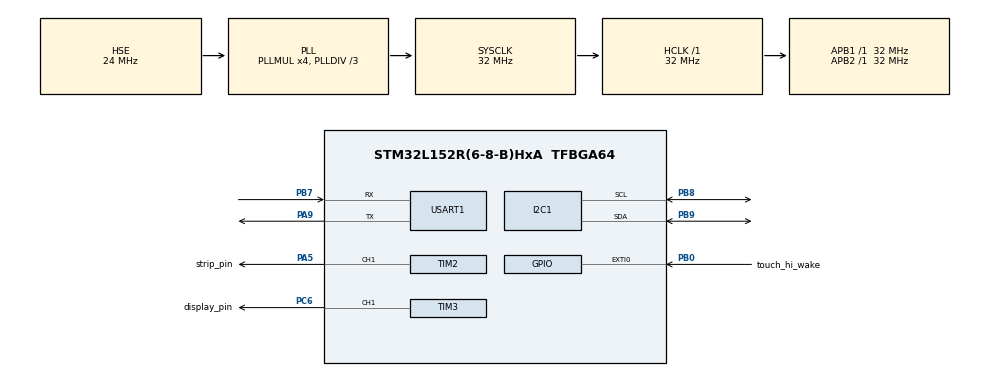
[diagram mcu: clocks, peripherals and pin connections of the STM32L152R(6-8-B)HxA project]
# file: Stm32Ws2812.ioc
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Dma.Request0=TIM2_CH1
Dma.Request1=TIM3_CH1/TRIG
Dma.TIM2_CH1.0.Direction=DMA_MEMORY_TO_PERIPH
Dma.TIM2_CH1.0.Instance=DMA1_Channel5
Dma.TIM2_CH1.0.MemDataAlignment=DMA_MDATAALIGN_HALFWORD
Dma.TIM2_CH1.0.MemInc=DMA_MINC_ENABLE
Dma.TIM2_CH1.0.Mode=DMA_CIRCULAR
Dma.TIM2_CH1.0.PeriphDataAlignment=DMA_PDATAALIGN_HALFWORD
Dma.TIM2_CH1.0.PeriphInc=DMA_PINC_DISABLE
Dma.TIM2_CH1.0.Priority=DMA_PRIORITY_LOW
Dma.TIM3_CH1/TRIG.1.Direction=DMA_PERIPH_TO_MEMORY
Dma.TIM3_CH1/TRIG.1.Instance=DMA1_Channel6
Dma.TIM3_CH1/TRIG.1.MemDataAlignment=DMA_MDATAALIGN_HALFWORD
Dma.TIM3_CH1/TRIG.1.MemInc=DMA_MINC_ENABLE
Dma.TIM3_CH1/TRIG.1.Mode=DMA_CIRCULAR
Dma.TIM3_CH1/TRIG.1.PeriphDataAlignment=DMA_PDATAALIGN_HALFWORD
Dma.TIM3_CH1/TRIG.1.PeriphInc=DMA_PINC_DISABLE
Dma.TIM3_CH1/TRIG.1.Priority=DMA_PRIORITY_LOW
FREERTOS.Mutexes01=cfgMutex,Dynamic,NULL
FREERTOS.Tasks01=ledsTask,0,128,LedsTask,Default,NULL,Dynamic,NULL,NULL;buttonsTask,0,128,ButtonsTask,Default,NULL,Dynamic,NULL,NULL;bleTask,0,256,BleTask,Default,NULL,Dynamic,NULL,NULL
FREERTOS.configTOTAL_HEAP_SIZE=4096
Mcu.Family=STM32L1
Mcu.Name=STM32L152R(6-8-B)HxA
Mcu.Package=TFBGA64
NVIC.DMA1_Channel5_IRQn=true\:5\:0\:false\:false\:true\:true\:false
NVIC.DMA1_Channel6_IRQn=true\:5\:0\:false\:false\:true\:true\:false
NVIC.EXTI0_IRQn=true\:5\:0\:false\:false\:true\:true\:true
NVIC.PriorityGroup=NVIC_PRIORITYGROUP_4
NVIC.TIM4_IRQn=true\:0\:0\:false\:false\:true\:false\:false
NVIC.TimeBase=TIM4_IRQn
NVIC.TimeBaseIP=TIM4
PA13.Mode=JTAG_5_pins
PA13.Signal=SYS_JTMS-SWDIO
PA14.Mode=JTAG_5_pins
PA14.Signal=SYS_JTCK-SWCLK
PA15.Mode=JTAG_5_pins
PA15.Signal=SYS_JTDI
PA5.GPIO_Label=strip_pin
PA5.GPIO_Speed=GPIO_SPEED_FREQ_VERY_HIGH
PA5.Signal=S_TIM2_CH1_ETR
PA9.Mode=Asynchronous
PA9.Signal=USART1_TX
PB0.GPIO_Label=touch_hi_wake
PB0.GPIO_PuPd=GPIO_PULLUP
PB0.Signal=GPXTI0
PB3.Mode=JTAG_5_pins
PB3.Signal=SYS_JTDO-TRACESWO
PB4.Mode=JTAG_5_pins
PB4.Signal=SYS_JTRST
PB7.Mode=Asynchronous
PB7.Signal=USART1_RX
PB8.Mode=I2C
PB8.Signal=I2C1_SCL
PB9.Mode=I2C
PB9.Signal=I2C1_SDA
PC14-OSC32_IN.Mode=LSE-External-Oscillator
PC14-OSC32_IN.Signal=RCC_OSC32_IN
PC15-OSC32_OUT.Mode=LSE-External-Oscillator
PC15-OSC32_OUT.Signal=RCC_OSC32_OUT
PC6.GPIO_Label=display_pin
PC6.GPIO_Speed=GPIO_SPEED_FREQ_VERY_HIGH
PC6.Signal=S_TIM3_CH1
PH0-OSC_IN.Mode=HSE-External-Oscillator
PH0-OSC_IN.Signal=RCC_OSC_IN
PH1-OSC_OUT.Mode=HSE-External-Oscillator
PH1-OSC_OUT.Signal=RCC_OSC_OUT
ProjectManager.HeapSize=0x200
ProjectManager.StackSize=0x400
ProjectManager.TargetToolchain=TrueSTUDIO
RCC.48MHZClocksFreq_Value=48000000
RCC.AHBFreq_Value=32000000
RCC.APB1Freq_Value=32000000
RCC.APB1TimFreq_Value=32000000
RCC.APB2Freq_Value=32000000
RCC.APB2TimFreq_Value=32000000
RCC.HCLKFreq_Value=32000000
RCC.HSE_VALUE=24000000
RCC.HSI_VALUE=16000000
RCC.MSI_VALUE=2097000
RCC.PLLDIV=RCC_PLL_DIV3
RCC.PLLMUL=RCC_PLL_MUL4
RCC.PLLSourceVirtual=RCC_PLLSOURCE_HSE
RCC.RTCClockSelection=RCC_RTCCLKSOURCE_LSE
RCC.RTCClockSelectionVirtual=RCC_RTCCLKSOURCE_LSE
RCC.SYSCLKFreq_VALUE=32000000
RCC.SYSCLKSource=RCC_SYSCLKSOURCE_PLLCLK
RCC.VCOOutputFreq_Value=96000000
SH.S_TIM2_CH1_ETR.0=TIM2_CH1,PWM Generation1 CH1
SH.S_TIM3_CH1.0=TIM3_CH1,PWM Generation1 CH1
TIM2.Channel-PWM\ Generation1\ CH1=TIM_CHANNEL_1
TIM2.OCFastMode_PWM-PWM\ Generation1\ CH1=TIM_OCFAST_ENABLE
TIM3.Channel-PWM\ Generation1\ CH1=TIM_CHANNEL_1
TIM3.OCFastMode_PWM-PWM\ Generation1\ CH1=TIM_OCFAST_ENABLE
USART1.VirtualMode=VM_ASYNC
VP_FREERTOS_VS_ENABLE.Mode=Enabled
VP_RTC_VS_RTC_Activate.Mode=RTC_Enabled
VP_SYS_VS_tim4.Mode=TIM4
VP_TIM2_VS_ClockSourceINT.Mode=Internal
VP_TIM3_VS_ClockSourceINT.Mode=Internal
board=custom

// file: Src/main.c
/* USER CODE BEGIN Header */
/**
  ******************************************************************************
  * @file           : main.c
  * @brief          : Main program body
  ******************************************************************************
  * This notice applies to any and all portions of this file
  * that are not between comment pairs USER CODE BEGIN and
  * USER CODE END. Other portions of this file, whether
  * inserted by the user or by software development tools
  * are owned by their respective copyright owners.
  *
  * Copyright (c) 2018 STMicroelectronics International N.V.
  * All rights reserved.
  *
  * Redistribution and use in source and binary forms, with or without
  * modification, are permitted, provided that the following conditions are met:
  *
  * 1. Redistribution of source code must retain the above copyright notice,
  *    this list of conditions and the following disclaimer.
  * 2. Redistributions in binary form must reproduce the above copyright notice,
  *    this list of conditions and the following disclaimer in the documentation
  *    and/or other materials provided with the distribution.
  * 3. Neither the name of STMicroelectronics nor the names of other
  *    contributors to this software may be used to endorse or promote products
  *    derived from this software without specific written permission.
  * 4. This software, including modifications and/or derivative works of this
  *    software, must execute solely and exclusively on microcontroller or
  *    microprocessor devices manufactured by or for STMicroelectronics.
  * 5. Redistribution and use of this software other than as permitted under
  *    this license is void and will automatically terminate your rights under
  *    this license.
  *
  * THIS SOFTWARE IS PROVIDED BY STMICROELECTRONICS AND CONTRIBUTORS "AS IS"
  * AND ANY EXPRESS, IMPLIED OR STATUTORY WARRANTIES, INCLUDING, BUT NOT
  * LIMITED TO, THE IMPLIED WARRANTIES OF MERCHANTABILITY, FITNESS FOR A
  * PARTICULAR PURPOSE AND NON-INFRINGEMENT OF THIRD PARTY INTELLECTUAL PROPERTY
  * RIGHTS ARE DISCLAIMED TO THE FULLEST EXTENT PERMITTED BY LAW. IN NO EVENT
  * SHALL STMICROELECTRONICS OR CONTRIBUTORS BE LIABLE FOR ANY DIRECT, INDIRECT,
  * INCIDENTAL, SPECIAL, EXEMPLARY, OR CONSEQUENTIAL DAMAGES (INCLUDING, BUT NOT
  * LIMITED TO, PROCUREMENT OF SUBSTITUTE GOODS OR SERVICES; LOSS OF USE, DATA,
  * OR PROFITS; OR BUSINESS INTERRUPTION) HOWEVER CAUSED AND ON ANY THEORY OF
  * LIABILITY, WHETHER IN CONTRACT, STRICT LIABILITY, OR TORT (INCLUDING
  * NEGLIGENCE OR OTHERWISE) ARISING IN ANY WAY OUT OF THE USE OF THIS SOFTWARE,
  * EVEN IF ADVISED OF THE POSSIBILITY OF SUCH DAMAGE.
  *
  ******************************************************************************
  */
/* USER CODE END Header */

#include "main.h"
#include "cmsis_os.h"

/* USER CODE BEGIN Includes */
#include "leds_task.h"
#include "ble_task.h"
#include "buttons_task.h"
#include "ws2812b.h"
/* USER CODE END Includes */

I2C_HandleTypeDef hi2c1;

RTC_HandleTypeDef hrtc;

TIM_HandleTypeDef htim2;
TIM_HandleTypeDef htim3;
DMA_HandleTypeDef hdma_tim2_ch1;
DMA_HandleTypeDef hdma_tim3_ch1;

UART_HandleTypeDef huart1;

osThreadId buttonsTaskHandle;
osThreadId bleTaskHandle;

void SystemClock_Config(void);
static void MX_DMA_Init(void);
static void MX_GPIO_Init(void);
static void MX_I2C1_Init(void);
static void MX_USART1_UART_Init(void);
static void MX_TIM2_Init(void);
static void MX_TIM3_Init(void);
static void MX_RTC_Init(void);

int main(void)
{

  /* MCU Configuration--------------------------------------------------------*/

  /* Reset of all peripherals, Initializes the Flash interface and the Systick. */
  HAL_Init();

  /* Configure the system clock */
  SystemClock_Config();

  /* Initialize all configured peripherals */
  MX_DMA_Init();
  MX_GPIO_Init();
  MX_I2C1_Init();
  MX_USART1_UART_Init();
  MX_TIM2_Init();
  MX_TIM3_Init();
  MX_RTC_Init();

  /* Create the mutex(es) */

  /* Create the thread(s) */
  CreateLedsTask();

  /* definition and creation of buttonsTask */
  osThreadDef(buttonsTask, ButtonsTask, osPriorityNormal, 0, 128);
  buttonsTaskHandle = osThreadCreate(osThread(buttonsTask), NULL);

  /* definition and creation of bleTask */
  osThreadDef(bleTask, BleTask, osPriorityNormal, 0, 256);
  bleTaskHandle = osThreadCreate(osThread(bleTask), NULL);

  /* Start scheduler */
  osKernelStart();

  /* We should never get here as control is now taken by the scheduler */

  /* Infinite loop */
  while (1)
  {

  }
}

void SystemClock_Config(void)
{
  RCC_OscInitTypeDef RCC_OscInitStruct = {0};
  RCC_ClkInitTypeDef RCC_ClkInitStruct = {0};
  RCC_PeriphCLKInitTypeDef PeriphClkInit = {0};

  /**Configure the main internal regulator output voltage
  */
  __HAL_PWR_VOLTAGESCALING_CONFIG(PWR_REGULATOR_VOLTAGE_SCALE1);
  /**Initializes the CPU, AHB and APB busses clocks
  */
  RCC_OscInitStruct.OscillatorType = RCC_OSCILLATORTYPE_HSE|RCC_OSCILLATORTYPE_LSE;
  RCC_OscInitStruct.HSEState = RCC_HSE_ON;
  RCC_OscInitStruct.LSEState = RCC_LSE_ON;
  RCC_OscInitStruct.PLL.PLLState = RCC_PLL_ON;
  RCC_OscInitStruct.PLL.PLLSource = RCC_PLLSOURCE_HSE;
  RCC_OscInitStruct.PLL.PLLMUL = RCC_PLL_MUL4;
  RCC_OscInitStruct.PLL.PLLDIV = RCC_PLL_DIV3;
  if (HAL_RCC_OscConfig(&RCC_OscInitStruct) != HAL_OK)
  {
    Error_Handler();
  }
  /**Initializes the CPU, AHB and APB busses clocks
  */
  RCC_ClkInitStruct.ClockType = RCC_CLOCKTYPE_HCLK|RCC_CLOCKTYPE_SYSCLK
                              |RCC_CLOCKTYPE_PCLK1|RCC_CLOCKTYPE_PCLK2;
  RCC_ClkInitStruct.SYSCLKSource = RCC_SYSCLKSOURCE_PLLCLK;
  RCC_ClkInitStruct.AHBCLKDivider = RCC_SYSCLK_DIV1;
  RCC_ClkInitStruct.APB1CLKDivider = RCC_HCLK_DIV1;
  RCC_ClkInitStruct.APB2CLKDivider = RCC_HCLK_DIV1;

  if (HAL_RCC_ClockConfig(&RCC_ClkInitStruct, FLASH_LATENCY_1) != HAL_OK)
  {
    Error_Handler();
  }
  PeriphClkInit.PeriphClockSelection = RCC_PERIPHCLK_RTC;
  PeriphClkInit.RTCClockSelection = RCC_RTCCLKSOURCE_LSE;
  if (HAL_RCCEx_PeriphCLKConfig(&PeriphClkInit) != HAL_OK)
  {
    Error_Handler();
  }
}

static void MX_I2C1_Init(void)
{

  hi2c1.Instance = I2C1;
  hi2c1.Init.ClockSpeed = 100000;
  hi2c1.Init.DutyCycle = I2C_DUTYCYCLE_2;
  hi2c1.Init.OwnAddress1 = 0;
  hi2c1.Init.AddressingMode = I2C_ADDRESSINGMODE_7BIT;
  hi2c1.Init.DualAddressMode = I2C_DUALADDRESS_DISABLE;
  hi2c1.Init.OwnAddress2 = 0;
  hi2c1.Init.GeneralCallMode = I2C_GENERALCALL_DISABLE;
  hi2c1.Init.NoStretchMode = I2C_NOSTRETCH_DISABLE;
  if (HAL_I2C_Init(&hi2c1) != HAL_OK)
  {
    Error_Handler();
  }

}

static void MX_RTC_Init(void)
{

  /**Initialize RTC Only
  */
  hrtc.Instance = RTC;
  hrtc.Init.HourFormat = RTC_HOURFORMAT_24;
  hrtc.Init.AsynchPrediv = 127;
  hrtc.Init.SynchPrediv = 255;
  hrtc.Init.OutPut = RTC_OUTPUT_DISABLE;
  hrtc.Init.OutPutPolarity = RTC_OUTPUT_POLARITY_HIGH;
  hrtc.Init.OutPutType = RTC_OUTPUT_TYPE_OPENDRAIN;
  if (HAL_RTC_Init(&hrtc) != HAL_OK)
  {
    Error_Handler();
  }

}

static void MX_TIM2_Init(void)
{

  TIM_ClockConfigTypeDef sClockSourceConfig = {0};
  TIM_MasterConfigTypeDef sMasterConfig = {0};
  TIM_OC_InitTypeDef sConfigOC = {0};

  htim2.Instance = TIM2;
  htim2.Init.Prescaler = (SystemCoreClock / WS2812B_TIMER_CLOCK_FREQ) - 1;
  htim2.Init.CounterMode = TIM_COUNTERMODE_UP;
  htim2.Init.Period = WS2812B_PERIOD - 1;
  htim2.Init.ClockDivision = TIM_CLOCKDIVISION_DIV1;
  if (HAL_TIM_Base_Init(&htim2) != HAL_OK)
  {
    Error_Handler();
  }
  sClockSourceConfig.ClockSource = TIM_CLOCKSOURCE_INTERNAL;
  if (HAL_TIM_ConfigClockSource(&htim2, &sClockSourceConfig) != HAL_OK)
  {
    Error_Handler();
  }
  if (HAL_TIM_PWM_Init(&htim2) != HAL_OK)
  {
    Error_Handler();
  }
  sMasterConfig.MasterOutputTrigger = TIM_TRGO_RESET;
  sMasterConfig.MasterSlaveMode = TIM_MASTERSLAVEMODE_DISABLE;
  if (HAL_TIMEx_MasterConfigSynchronization(&htim2, &sMasterConfig) != HAL_OK)
  {
    Error_Handler();
  }
  sConfigOC.OCMode = TIM_OCMODE_PWM1;
  sConfigOC.Pulse = 0;
  sConfigOC.OCPolarity = TIM_OCPOLARITY_HIGH;
  sConfigOC.OCFastMode = TIM_OCFAST_ENABLE;
  if (HAL_TIM_PWM_ConfigChannel(&htim2, &sConfigOC, TIM_CHANNEL_1) != HAL_OK)
  {
    Error_Handler();
  }
  HAL_TIM_MspPostInit(&htim2);

}

static void MX_TIM3_Init(void)
{

  TIM_ClockConfigTypeDef sClockSourceConfig = {0};
  TIM_MasterConfigTypeDef sMasterConfig = {0};
  TIM_OC_InitTypeDef sConfigOC = {0};

  htim3.Instance = TIM3;
  htim3.Init.Prescaler = (SystemCoreClock / WS2812B_TIMER_CLOCK_FREQ) - 1;
  htim3.Init.CounterMode = TIM_COUNTERMODE_UP;
  htim3.Init.Period = WS2812B_PERIOD - 1;
  htim3.Init.ClockDivision = TIM_CLOCKDIVISION_DIV1;
  if (HAL_TIM_Base_Init(&htim3) != HAL_OK)
  {
    Error_Handler();
  }
  sClockSourceConfig.ClockSource = TIM_CLOCKSOURCE_INTERNAL;
  if (HAL_TIM_ConfigClockSource(&htim3, &sClockSourceConfig) != HAL_OK)
  {
    Error_Handler();
  }
  if (HAL_TIM_PWM_Init(&htim3) != HAL_OK)
  {
    Error_Handler();
  }
  sMasterConfig.MasterOutputTrigger = TIM_TRGO_RESET;
  sMasterConfig.MasterSlaveMode = TIM_MASTERSLAVEMODE_DISABLE;
  if (HAL_TIMEx_MasterConfigSynchronization(&htim3, &sMasterConfig) != HAL_OK)
  {
    Error_Handler();
  }
  sConfigOC.OCMode = TIM_OCMODE_PWM1;
  sConfigOC.Pulse = 0;
  sConfigOC.OCPolarity = TIM_OCPOLARITY_HIGH;
  sConfigOC.OCFastMode = TIM_OCFAST_ENABLE;
  if (HAL_TIM_PWM_ConfigChannel(&htim3, &sConfigOC, TIM_CHANNEL_1) != HAL_OK)
  {
    Error_Handler();
  }
  HAL_TIM_MspPostInit(&htim3);

}

static void MX_USART1_UART_Init(void)
{

  huart1.Instance = USART1;
  huart1.Init.BaudRate = 115200;
  huart1.Init.WordLength = UART_WORDLENGTH_8B;
  huart1.Init.StopBits = UART_STOPBITS_1;
  huart1.Init.Parity = UART_PARITY_NONE;
  huart1.Init.Mode = UART_MODE_TX_RX;
  huart1.Init.HwFlowCtl = UART_HWCONTROL_NONE;
  huart1.Init.OverSampling = UART_OVERSAMPLING_16;
  if (HAL_UART_Init(&huart1) != HAL_OK)
  {
    Error_Handler();
  }

}

static void MX_DMA_Init(void)
{
  /* DMA controller clock enable */
  __HAL_RCC_DMA1_CLK_ENABLE();

  /* DMA interrupt init */
  /* DMA1_Channel5_IRQn interrupt configuration */
  HAL_NVIC_SetPriority(DMA1_Channel5_IRQn, 5, 0);
  HAL_NVIC_EnableIRQ(DMA1_Channel5_IRQn);
  /* DMA1_Channel6_IRQn interrupt configuration */
  HAL_NVIC_SetPriority(DMA1_Channel6_IRQn, 5, 0);
  HAL_NVIC_EnableIRQ(DMA1_Channel6_IRQn);

}

static void MX_GPIO_Init(void)
{
  GPIO_InitTypeDef GPIO_InitStruct = {0};

  /* GPIO Ports Clock Enable */
  __HAL_RCC_GPIOC_CLK_ENABLE();
  __HAL_RCC_GPIOB_CLK_ENABLE();
  __HAL_RCC_GPIOA_CLK_ENABLE();
  __HAL_RCC_GPIOH_CLK_ENABLE();

  /*Configure GPIO pin : touch_hi_wake_Pin */
  GPIO_InitStruct.Pin = touch_hi_wake_Pin;
  GPIO_InitStruct.Mode = GPIO_MODE_IT_FALLING;
  GPIO_InitStruct.Pull = GPIO_PULLUP;
  HAL_GPIO_Init(touch_hi_wake_GPIO_Port, &GPIO_InitStruct);

  /* EXTI interrupt init*/
  HAL_NVIC_SetPriority(EXTI0_IRQn, 5, 0);
  HAL_NVIC_EnableIRQ(EXTI0_IRQn);
}

void HAL_TIM_PeriodElapsedCallback(TIM_HandleTypeDef *htim)
{
  if (htim->Instance == TIM4) {
    HAL_IncTick();
  }
}

void HAL_GPIO_EXTI_Callback(uint16_t GPIO_Pin)
{
	if(GPIO_Pin == touch_hi_wake_Pin)
	{
		//wakeUp task to read touch controller
		osSignalSet(buttonsTaskHandle, TASK_READ_I2C_SIGNAL);
	}
}

uint8_t UART_ReceiveData(UART_HandleTypeDef *huart)
{
	return (uint8_t)(huart->Instance->DR & (uint8_t)0x00FF);
}

/**
  * @brief This function handles USART1 global interrupt.
  */
void USART1_IRQHandler(void)
{
	uint32_t tmp_flag = __HAL_UART_GET_FLAG(&huart1, UART_FLAG_RXNE);
	uint32_t tmp_it_source = __HAL_UART_GET_IT_SOURCE(&huart1, UART_IT_RXNE);

	if((tmp_flag != RESET) && (tmp_it_source != RESET)) //enter interrupt when STM32 receive data.
	{
		uint8_t rx = UART_ReceiveData(&huart1); //receive a char
		BleTaskPutQueueByte(rx);
	}
}

void Error_Handler(void)
{
}

/************************ (C) COPYRIGHT STMicroelectronics *****END OF FILE****/
